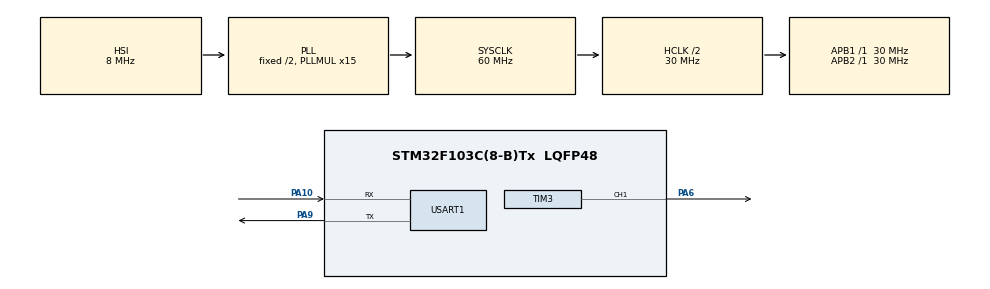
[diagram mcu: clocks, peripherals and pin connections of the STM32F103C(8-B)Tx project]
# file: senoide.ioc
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Dma.Request0=TIM3_CH1/TRIG
Dma.TIM3_CH1/TRIG.0.Direction=DMA_MEMORY_TO_PERIPH
Dma.TIM3_CH1/TRIG.0.Instance=DMA1_Channel6
Dma.TIM3_CH1/TRIG.0.MemDataAlignment=DMA_MDATAALIGN_HALFWORD
Dma.TIM3_CH1/TRIG.0.MemInc=DMA_MINC_ENABLE
Dma.TIM3_CH1/TRIG.0.Mode=DMA_CIRCULAR
Dma.TIM3_CH1/TRIG.0.PeriphDataAlignment=DMA_PDATAALIGN_HALFWORD
Dma.TIM3_CH1/TRIG.0.PeriphInc=DMA_PINC_DISABLE
Dma.TIM3_CH1/TRIG.0.Priority=DMA_PRIORITY_LOW
Mcu.Family=STM32F1
Mcu.Name=STM32F103C(8-B)Tx
Mcu.Package=LQFP48
NVIC.DMA1_Channel6_IRQn=true\:0\:0\:false\:false\:true\:false\:true\:true
NVIC.PriorityGroup=NVIC_PRIORITYGROUP_4
NVIC.USART1_IRQn=true\:0\:0\:false\:false\:true\:true\:true\:true
PA10.Mode=Asynchronous
PA10.Signal=USART1_RX
PA13.Mode=Serial_Wire
PA13.Signal=SYS_JTMS-SWDIO
PA14.Mode=Serial_Wire
PA14.Signal=SYS_JTCK-SWCLK
PA6.Signal=S_TIM3_CH1
PA9.Mode=Asynchronous
PA9.Signal=USART1_TX
ProjectManager.HeapSize=0x200
ProjectManager.StackSize=0x400
ProjectManager.TargetToolchain=STM32CubeIDE
RCC.AHBCLKDivider=RCC_SYSCLK_DIV2
RCC.AHBFreq_Value=30000000
RCC.APB1Freq_Value=30000000
RCC.APB1TimFreq_Value=30000000
RCC.APB2Freq_Value=30000000
RCC.APB2TimFreq_Value=30000000
RCC.HCLKFreq_Value=30000000
RCC.PLLMUL=RCC_PLL_MUL15
RCC.SYSCLKFreq_VALUE=60000000
RCC.SYSCLKSource=RCC_SYSCLKSOURCE_PLLCLK
RCC.USBFreq_Value=60000000
SH.S_TIM3_CH1.0=TIM3_CH1,PWM Generation1 CH1
TIM3.Channel-PWM\ Generation1\ CH1=TIM_CHANNEL_1
TIM3.Period=200-1
TIM3.Prescaler=10-1
USART1.VirtualMode=VM_ASYNC
VP_TIM3_VS_ClockSourceITR.Mode=TriggerSource_ITR0
board=custom

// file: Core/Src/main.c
/* USER CODE BEGIN Header */
/**
  ******************************************************************************
  * @file           : main.c
  * @brief          : Gerador de Onda Senoidal com Frequência Variável via UART
  * Adaptado para o Lab Timer-UART STM32
  ******************************************************************************
  */
/* USER CODE END Header */
#include "main.h"

/* USER CODE BEGIN Includes */
#include <math.h>
#include <stdlib.h>
#include <string.h>
#include <stdio.h>

// Garante o valor de PI com alta precisão para reduzir o THD
#ifndef M_PI
#define M_PI 3.14159265358979323846
#endif
/* USER CODE END Includes */

TIM_HandleTypeDef htim3;
DMA_HandleTypeDef hdma_tim3_ch1_trig;

UART_HandleTypeDef huart1;

/* USER CODE BEGIN PV */
uint16_t seno[250];
uint8_t i;

// Variáveis para a UART (Polling)
uint8_t rx_data;
char rx_buffer[10];
uint8_t rx_index = 0;
/* USER CODE END PV */

void SystemClock_Config(void);
static void MX_GPIO_Init(void);
static void MX_DMA_Init(void);
static void MX_TIM3_Init(void);
static void MX_USART1_UART_Init(void);

/* USER CODE BEGIN 0 */

// A função HAL_UART_RxCpltCallback foi removida daqui, pois agora usamos Polling!

/* USER CODE END 0 */

int main(void)
{

  /* MCU Configuration--------------------------------------------------------*/

  /* Reset of all peripherals, Initializes the Flash interface and the Systick. */
  HAL_Init();

  /* Configure the system clock */
  SystemClock_Config();

  /* Initialize all configured peripherals */
  MX_GPIO_Init();
  MX_DMA_Init();
  MX_TIM3_Init();
  MX_USART1_UART_Init();

  /* USER CODE BEGIN 2 */

  // Calcula e inicia a onda via DMA (Roda no hardware, livre da CPU!)
  for (i = 0; i < 250; i++){
      seno[i] = (uint16_t)(((sin((double)i * (M_PI * 2.0) / 250.0)) + 1.0) * 100.0);
  }
  HAL_TIM_PWM_Start_DMA(&htim3, TIM_CHANNEL_1, (uint32_t *)seno, 250);

  // Mensagem inicial
  char msg_inicio[] = "Gerador Senoidal Iniciado. Digite a freq (10 a 120 Hz):\r\n";
  HAL_UART_Transmit(&huart1, (uint8_t*)msg_inicio, strlen(msg_inicio), 100);

  /* USER CODE END 2 */

  /* Infinite loop */
  /* USER CODE BEGIN WHILE */
  while (1)
  {
      // Fica lendo a porta Serial de forma direta (Polling). Sem travar a onda!
      if (HAL_UART_Receive(&huart1, &rx_data, 1, 10) == HAL_OK) {

          // Eco: Escreve na tela a letra que você acabou de apertar
          HAL_UART_Transmit(&huart1, &rx_data, 1, 10);

          // Se você apertar Enter (\n ou \r)
          if (rx_data == '\n' || rx_data == '\r') {
              if (rx_index > 0) {
                  rx_buffer[rx_index] = '\0';
                  int nova_freq = atoi(rx_buffer);
                  char msg_retorno[50];

                  if (nova_freq >= 10 && nova_freq <= 120) {
                      uint32_t novo_psc = (1200 / nova_freq) - 1;
                      __HAL_TIM_SET_PRESCALER(&htim3, novo_psc);
                      sprintf(msg_retorno, "\r\n=> Sucesso! Freq atualizada: %d Hz\r\n\n", nova_freq);
                  } else {
                      sprintf(msg_retorno, "\r\n=> ERRO: Limite (10-120)\r\n\n");
                  }

                  HAL_UART_Transmit(&huart1, (uint8_t*)msg_retorno, strlen(msg_retorno), 100);
                  rx_index = 0; // Limpa para a próxima digitação
              }
          } else {
              // Se for um número, guarda na memória
              if (rx_index < 9 && rx_data >= '0' && rx_data <= '9') {
                  rx_buffer[rx_index++] = rx_data;
              }
          }
      }
    /* USER CODE END WHILE */

  }
}

void SystemClock_Config(void)
{
  RCC_OscInitTypeDef RCC_OscInitStruct = {0};
  RCC_ClkInitTypeDef RCC_ClkInitStruct = {0};

  /** Initializes the RCC Oscillators according to the specified parameters
  * in the RCC_OscInitTypeDef structure.
  */
  RCC_OscInitStruct.OscillatorType = RCC_OSCILLATORTYPE_HSI;
  RCC_OscInitStruct.HSIState = RCC_HSI_ON;
  RCC_OscInitStruct.HSICalibrationValue = RCC_HSICALIBRATION_DEFAULT;
  RCC_OscInitStruct.PLL.PLLState = RCC_PLL_ON;
  RCC_OscInitStruct.PLL.PLLSource = RCC_PLLSOURCE_HSI_DIV2;
  RCC_OscInitStruct.PLL.PLLMUL = RCC_PLL_MUL15;
  if (HAL_RCC_OscConfig(&RCC_OscInitStruct) != HAL_OK)
  {
    Error_Handler();
  }

  /** Initializes the CPU, AHB and APB buses clocks
  */
  RCC_ClkInitStruct.ClockType = RCC_CLOCKTYPE_HCLK|RCC_CLOCKTYPE_SYSCLK
                              |RCC_CLOCKTYPE_PCLK1|RCC_CLOCKTYPE_PCLK2;
  RCC_ClkInitStruct.SYSCLKSource = RCC_SYSCLKSOURCE_PLLCLK;
  RCC_ClkInitStruct.AHBCLKDivider = RCC_SYSCLK_DIV2;
  RCC_ClkInitStruct.APB1CLKDivider = RCC_HCLK_DIV1;
  RCC_ClkInitStruct.APB2CLKDivider = RCC_HCLK_DIV1;

  if (HAL_RCC_ClockConfig(&RCC_ClkInitStruct, FLASH_LATENCY_2) != HAL_OK)
  {
    Error_Handler();
  }
}

static void MX_TIM3_Init(void)
{
  TIM_SlaveConfigTypeDef sSlaveConfig = {0};
  TIM_MasterConfigTypeDef sMasterConfig = {0};
  TIM_OC_InitTypeDef sConfigOC = {0};

  htim3.Instance = TIM3;
  htim3.Init.Prescaler = 10-1;
  htim3.Init.CounterMode = TIM_COUNTERMODE_UP;
  htim3.Init.Period = 200-1;
  htim3.Init.ClockDivision = TIM_CLOCKDIVISION_DIV1;
  htim3.Init.AutoReloadPreload = TIM_AUTORELOAD_PRELOAD_DISABLE;
  if (HAL_TIM_Base_Init(&htim3) != HAL_OK)
  {
    Error_Handler();
  }
  if (HAL_TIM_PWM_Init(&htim3) != HAL_OK)
  {
    Error_Handler();
  }
  sSlaveConfig.SlaveMode = TIM_SLAVEMODE_DISABLE;
  sSlaveConfig.InputTrigger = TIM_TS_ITR0;
  if (HAL_TIM_SlaveConfigSynchro(&htim3, &sSlaveConfig) != HAL_OK)
  {
    Error_Handler();
  }
  sMasterConfig.MasterOutputTrigger = TIM_TRGO_RESET;
  sMasterConfig.MasterSlaveMode = TIM_MASTERSLAVEMODE_DISABLE;
  if (HAL_TIMEx_MasterConfigSynchronization(&htim3, &sMasterConfig) != HAL_OK)
  {
    Error_Handler();
  }
  sConfigOC.OCMode = TIM_OCMODE_PWM1;
  sConfigOC.Pulse = 0;
  sConfigOC.OCPolarity = TIM_OCPOLARITY_HIGH;
  sConfigOC.OCFastMode = TIM_OCFAST_DISABLE;
  if (HAL_TIM_PWM_ConfigChannel(&htim3, &sConfigOC, TIM_CHANNEL_1) != HAL_OK)
  {
    Error_Handler();
  }
  HAL_TIM_MspPostInit(&htim3);
}

static void MX_USART1_UART_Init(void)
{
  huart1.Instance = USART1;
  huart1.Init.BaudRate = 9600;
  huart1.Init.WordLength = UART_WORDLENGTH_8B;
  huart1.Init.StopBits = UART_STOPBITS_1;
  huart1.Init.Parity = UART_PARITY_NONE;
  huart1.Init.Mode = UART_MODE_TX_RX;
  huart1.Init.HwFlowCtl = UART_HWCONTROL_NONE;
  huart1.Init.OverSampling = UART_OVERSAMPLING_16;
  if (HAL_UART_Init(&huart1) != HAL_OK)
  {
    Error_Handler();
  }
}

static void MX_DMA_Init(void)
{
  /* DMA controller clock enable */
  __HAL_RCC_DMA1_CLK_ENABLE();

  /* DMA interrupt init */
  /* DMA1_Channel6_IRQn interrupt configuration */
  HAL_NVIC_SetPriority(DMA1_Channel6_IRQn, 0, 0);
  HAL_NVIC_EnableIRQ(DMA1_Channel6_IRQn);
}

static void MX_GPIO_Init(void)
{
  /* GPIO Ports Clock Enable */
  __HAL_RCC_GPIOA_CLK_ENABLE();
}

void Error_Handler(void)
{
  __disable_irq();
  while (1)
  {
  }
}
